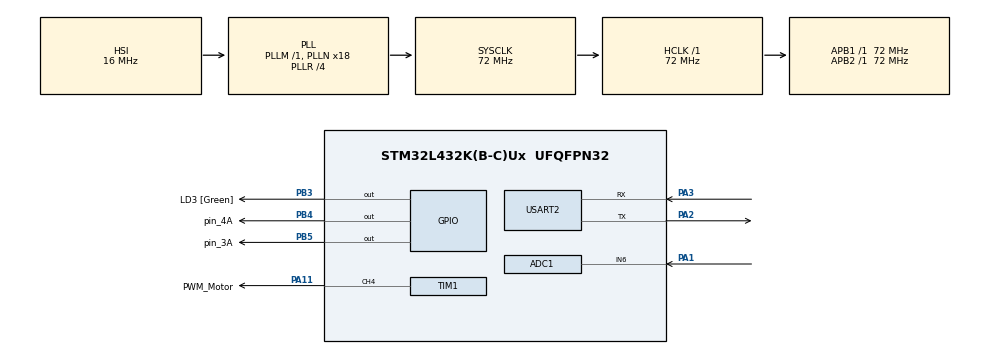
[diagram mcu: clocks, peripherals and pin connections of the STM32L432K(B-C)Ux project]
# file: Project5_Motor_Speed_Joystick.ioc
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ADC1.Channel-0\#ChannelRegularConversion=ADC_CHANNEL_6
ADC1.NbrOfConversionFlag=1
ADC1.OffsetNumber-0\#ChannelRegularConversion=ADC_OFFSET_NONE
ADC1.Rank-0\#ChannelRegularConversion=1
ADC1.Resolution=ADC_RESOLUTION_8B
ADC1.SamplingTime-0\#ChannelRegularConversion=ADC_SAMPLETIME_2CYCLES_5
ADC1.master=1
Mcu.Family=STM32L4
Mcu.Name=STM32L432K(B-C)Ux
Mcu.Package=UFQFPN32
NVIC.PriorityGroup=NVIC_PRIORITYGROUP_4
PA1.Signal=ADCx_IN6
PA11.GPIO_Label=PWM_Motor
PA11.Signal=S_TIM1_CH4
PA2.Mode=Asynchronous
PA2.Signal=USART2_TX
PA3.Mode=Asynchronous
PA3.Signal=USART2_RX
PB3\ (JTDO-TRACESWO).GPIO_Label=LD3 [Green]
PB3\ (JTDO-TRACESWO).Signal=GPIO_Output
PB4\ (NJTRST).GPIO_Label=pin_4A
PB4\ (NJTRST).Signal=GPIO_Output
PB5.GPIO_Label=pin_3A
PB5.Signal=GPIO_Output
ProjectManager.HeapSize=0x200
ProjectManager.StackSize=0x400
ProjectManager.TargetToolchain=STM32CubeIDE
RCC.ADCFreq_Value=64000000
RCC.AHBFreq_Value=72000000
RCC.APB1Freq_Value=72000000
RCC.APB1TimFreq_Value=72000000
RCC.APB2Freq_Value=72000000
RCC.APB2TimFreq_Value=72000000
RCC.CortexFreq_Value=72000000
RCC.HCLKFreq_Value=72000000
RCC.HSI16_VALUE=16000000
RCC.HSI48_VALUE=48000000
RCC.HSI_VALUE=16000000
RCC.MSI_VALUE=4000000
RCC.PLLMUL=RCC_PLLMUL_4
RCC.PLLN=18
RCC.PLLR=RCC_PLLR_DIV4
RCC.PLLSourceVirtual=RCC_PLLSOURCE_HSI
RCC.SYSCLKFreq_VALUE=72000000
RCC.SYSCLKSource=RCC_SYSCLKSOURCE_PLLCLK
RCC.USBFreq_Value=64000000
RCC.VCOOutputFreq_Value=288000000
SH.ADCx_IN6.0=ADC1_IN6,IN6-Single-Ended
SH.S_TIM1_CH4.0=TIM1_CH4,PWM Generation4 CH4
TIM1.AutoReloadPreload=TIM_AUTORELOAD_PRELOAD_ENABLE
TIM1.Channel-PWM\ Generation4\ CH4=TIM_CHANNEL_4
TIM1.Period=510
TIM1.Prescaler=71
USART2.VirtualMode-Asynchronous=VM_ASYNC
VP_TIM1_VS_ClockSourceINT.Mode=Internal
board=NUCLEO-L432KC

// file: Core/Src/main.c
/* USER CODE BEGIN Header */
/**
  ******************************************************************************
  * @file           : main.c
  * @brief          : Main program body
  ******************************************************************************
  * @attention
  *
  * Copyright (c) 2026 STMicroelectronics.
  * All rights reserved.
  *
  * This software is licensed under terms that can be found in the LICENSE file
  * in the root directory of this software component.
  * If no LICENSE file comes with this software, it is provided AS-IS.
  *
  ******************************************************************************
  */
/* USER CODE END Header */
#include "main.h"

/* USER CODE BEGIN Includes */
#include <stdio.h>
#include <string.h>
/* USER CODE END Includes */

ADC_HandleTypeDef hadc1;

TIM_HandleTypeDef htim1;

UART_HandleTypeDef huart2;

void SystemClock_Config(void);
static void MX_GPIO_Init(void);
static void MX_USART2_UART_Init(void);
static void MX_TIM1_Init(void);
static void MX_ADC1_Init(void);

int main(void)
{

  /* MCU Configuration--------------------------------------------------------*/

  /* Reset of all peripherals, Initializes the Flash interface and the Systick. */
  HAL_Init();

  /* Configure the system clock */
  SystemClock_Config();

  /* Initialize all configured peripherals */
  MX_GPIO_Init();
  MX_USART2_UART_Init();
  MX_TIM1_Init();
  MX_ADC1_Init();
  /* USER CODE BEGIN 2 */
  uint16_t ADC_RES = 0;
  HAL_TIM_PWM_Start(&htim1, TIM_CHANNEL_4);
  char msg[50];
//  HAL_ADCEx_Calibration_Start(&hadc1, );

  /* USER CODE END 2 */

  /* Infinite loop */
  /* USER CODE BEGIN WHILE */
  while (1)
  {
	  HAL_ADC_Start(&hadc1);
	  HAL_ADC_PollForConversion(&hadc1, 1);
	  ADC_RES = HAL_ADC_GetValue(&hadc1);
	  HAL_GPIO_WritePin(pin_4A_GPIO_Port, pin_4A_Pin, GPIO_PIN_SET);
	  HAL_GPIO_WritePin(pin_3A_GPIO_Port, pin_3A_Pin, GPIO_PIN_RESET);
	  TIM1->CCR4 = ADC_RES * 2;
	  sprintf(msg, "ADC Value = %d\r\n", ADC_RES);
	  HAL_UART_Transmit(&huart2, (uint8_t*)msg, strlen(msg), 500);

	  HAL_Delay(50);
    /* USER CODE END WHILE */

  }
}

void SystemClock_Config(void)
{
  RCC_OscInitTypeDef RCC_OscInitStruct = {0};
  RCC_ClkInitTypeDef RCC_ClkInitStruct = {0};

  /** Configure the main internal regulator output voltage
  */
  if (HAL_PWREx_ControlVoltageScaling(PWR_REGULATOR_VOLTAGE_SCALE1) != HAL_OK)
  {
    Error_Handler();
  }

  /** Initializes the RCC Oscillators according to the specified parameters
  * in the RCC_OscInitTypeDef structure.
  */
  RCC_OscInitStruct.OscillatorType = RCC_OSCILLATORTYPE_HSI;
  RCC_OscInitStruct.HSIState = RCC_HSI_ON;
  RCC_OscInitStruct.HSICalibrationValue = RCC_HSICALIBRATION_DEFAULT;
  RCC_OscInitStruct.PLL.PLLState = RCC_PLL_ON;
  RCC_OscInitStruct.PLL.PLLSource = RCC_PLLSOURCE_HSI;
  RCC_OscInitStruct.PLL.PLLM = 1;
  RCC_OscInitStruct.PLL.PLLN = 18;
  RCC_OscInitStruct.PLL.PLLP = RCC_PLLP_DIV7;
  RCC_OscInitStruct.PLL.PLLQ = RCC_PLLQ_DIV2;
  RCC_OscInitStruct.PLL.PLLR = RCC_PLLR_DIV4;
  if (HAL_RCC_OscConfig(&RCC_OscInitStruct) != HAL_OK)
  {
    Error_Handler();
  }

  /** Initializes the CPU, AHB and APB buses clocks
  */
  RCC_ClkInitStruct.ClockType = RCC_CLOCKTYPE_HCLK|RCC_CLOCKTYPE_SYSCLK
                              |RCC_CLOCKTYPE_PCLK1|RCC_CLOCKTYPE_PCLK2;
  RCC_ClkInitStruct.SYSCLKSource = RCC_SYSCLKSOURCE_PLLCLK;
  RCC_ClkInitStruct.AHBCLKDivider = RCC_SYSCLK_DIV1;
  RCC_ClkInitStruct.APB1CLKDivider = RCC_HCLK_DIV1;
  RCC_ClkInitStruct.APB2CLKDivider = RCC_HCLK_DIV1;

  if (HAL_RCC_ClockConfig(&RCC_ClkInitStruct, FLASH_LATENCY_4) != HAL_OK)
  {
    Error_Handler();
  }
}

static void MX_ADC1_Init(void)
{

  ADC_ChannelConfTypeDef sConfig = {0};

  /** Common config
  */
  hadc1.Instance = ADC1;
  hadc1.Init.ClockPrescaler = ADC_CLOCK_ASYNC_DIV1;
  hadc1.Init.Resolution = ADC_RESOLUTION_8B;
  hadc1.Init.DataAlign = ADC_DATAALIGN_RIGHT;
  hadc1.Init.ScanConvMode = ADC_SCAN_DISABLE;
  hadc1.Init.EOCSelection = ADC_EOC_SINGLE_CONV;
  hadc1.Init.LowPowerAutoWait = DISABLE;
  hadc1.Init.ContinuousConvMode = DISABLE;
  hadc1.Init.NbrOfConversion = 1;
  hadc1.Init.DiscontinuousConvMode = DISABLE;
  hadc1.Init.ExternalTrigConv = ADC_SOFTWARE_START;
  hadc1.Init.ExternalTrigConvEdge = ADC_EXTERNALTRIGCONVEDGE_NONE;
  hadc1.Init.DMAContinuousRequests = DISABLE;
  hadc1.Init.Overrun = ADC_OVR_DATA_PRESERVED;
  hadc1.Init.OversamplingMode = DISABLE;
  if (HAL_ADC_Init(&hadc1) != HAL_OK)
  {
    Error_Handler();
  }

  /** Configure Regular Channel
  */
  sConfig.Channel = ADC_CHANNEL_6;
  sConfig.Rank = ADC_REGULAR_RANK_1;
  sConfig.SamplingTime = ADC_SAMPLETIME_2CYCLES_5;
  sConfig.SingleDiff = ADC_SINGLE_ENDED;
  sConfig.OffsetNumber = ADC_OFFSET_NONE;
  sConfig.Offset = 0;
  if (HAL_ADC_ConfigChannel(&hadc1, &sConfig) != HAL_OK)
  {
    Error_Handler();
  }

}

static void MX_TIM1_Init(void)
{

  TIM_ClockConfigTypeDef sClockSourceConfig = {0};
  TIM_MasterConfigTypeDef sMasterConfig = {0};
  TIM_OC_InitTypeDef sConfigOC = {0};
  TIM_BreakDeadTimeConfigTypeDef sBreakDeadTimeConfig = {0};

  htim1.Instance = TIM1;
  htim1.Init.Prescaler = 71;
  htim1.Init.CounterMode = TIM_COUNTERMODE_UP;
  htim1.Init.Period = 510;
  htim1.Init.ClockDivision = TIM_CLOCKDIVISION_DIV1;
  htim1.Init.RepetitionCounter = 0;
  htim1.Init.AutoReloadPreload = TIM_AUTORELOAD_PRELOAD_ENABLE;
  if (HAL_TIM_Base_Init(&htim1) != HAL_OK)
  {
    Error_Handler();
  }
  sClockSourceConfig.ClockSource = TIM_CLOCKSOURCE_INTERNAL;
  if (HAL_TIM_ConfigClockSource(&htim1, &sClockSourceConfig) != HAL_OK)
  {
    Error_Handler();
  }
  if (HAL_TIM_PWM_Init(&htim1) != HAL_OK)
  {
    Error_Handler();
  }
  sMasterConfig.MasterOutputTrigger = TIM_TRGO_RESET;
  sMasterConfig.MasterOutputTrigger2 = TIM_TRGO2_RESET;
  sMasterConfig.MasterSlaveMode = TIM_MASTERSLAVEMODE_DISABLE;
  if (HAL_TIMEx_MasterConfigSynchronization(&htim1, &sMasterConfig) != HAL_OK)
  {
    Error_Handler();
  }
  sConfigOC.OCMode = TIM_OCMODE_PWM1;
  sConfigOC.Pulse = 0;
  sConfigOC.OCPolarity = TIM_OCPOLARITY_HIGH;
  sConfigOC.OCFastMode = TIM_OCFAST_DISABLE;
  sConfigOC.OCIdleState = TIM_OCIDLESTATE_RESET;
  sConfigOC.OCNIdleState = TIM_OCNIDLESTATE_RESET;
  if (HAL_TIM_PWM_ConfigChannel(&htim1, &sConfigOC, TIM_CHANNEL_4) != HAL_OK)
  {
    Error_Handler();
  }
  sBreakDeadTimeConfig.OffStateRunMode = TIM_OSSR_DISABLE;
  sBreakDeadTimeConfig.OffStateIDLEMode = TIM_OSSI_DISABLE;
  sBreakDeadTimeConfig.LockLevel = TIM_LOCKLEVEL_OFF;
  sBreakDeadTimeConfig.DeadTime = 0;
  sBreakDeadTimeConfig.BreakState = TIM_BREAK_DISABLE;
  sBreakDeadTimeConfig.BreakPolarity = TIM_BREAKPOLARITY_HIGH;
  sBreakDeadTimeConfig.BreakFilter = 0;
  sBreakDeadTimeConfig.Break2State = TIM_BREAK2_DISABLE;
  sBreakDeadTimeConfig.Break2Polarity = TIM_BREAK2POLARITY_HIGH;
  sBreakDeadTimeConfig.Break2Filter = 0;
  sBreakDeadTimeConfig.AutomaticOutput = TIM_AUTOMATICOUTPUT_DISABLE;
  if (HAL_TIMEx_ConfigBreakDeadTime(&htim1, &sBreakDeadTimeConfig) != HAL_OK)
  {
    Error_Handler();
  }
  HAL_TIM_MspPostInit(&htim1);

}

static void MX_USART2_UART_Init(void)
{

  huart2.Instance = USART2;
  huart2.Init.BaudRate = 115200;
  huart2.Init.WordLength = UART_WORDLENGTH_8B;
  huart2.Init.StopBits = UART_STOPBITS_1;
  huart2.Init.Parity = UART_PARITY_NONE;
  huart2.Init.Mode = UART_MODE_TX_RX;
  huart2.Init.HwFlowCtl = UART_HWCONTROL_NONE;
  huart2.Init.OverSampling = UART_OVERSAMPLING_16;
  huart2.Init.OneBitSampling = UART_ONE_BIT_SAMPLE_DISABLE;
  huart2.AdvancedInit.AdvFeatureInit = UART_ADVFEATURE_NO_INIT;
  if (HAL_UART_Init(&huart2) != HAL_OK)
  {
    Error_Handler();
  }

}

static void MX_GPIO_Init(void)
{
  GPIO_InitTypeDef GPIO_InitStruct = {0};

  /* GPIO Ports Clock Enable */
  __HAL_RCC_GPIOA_CLK_ENABLE();
  __HAL_RCC_GPIOB_CLK_ENABLE();

  /*Configure GPIO pin Output Level */
  HAL_GPIO_WritePin(GPIOB, LD3_Pin|pin_4A_Pin|pin_3A_Pin, GPIO_PIN_RESET);

  /*Configure GPIO pins : LD3_Pin pin_4A_Pin pin_3A_Pin */
  GPIO_InitStruct.Pin = LD3_Pin|pin_4A_Pin|pin_3A_Pin;
  GPIO_InitStruct.Mode = GPIO_MODE_OUTPUT_PP;
  GPIO_InitStruct.Pull = GPIO_NOPULL;
  GPIO_InitStruct.Speed = GPIO_SPEED_FREQ_LOW;
  HAL_GPIO_Init(GPIOB, &GPIO_InitStruct);

}

void Error_Handler(void)
{
  __disable_irq();
  while (1)
  {
  }
}
